# STM32L4A6 register map
File version: 1.0
CPU: CM4 r0p1, little endian, MPU, FPU, 4 interrupt priority bits
Registers are 32-bit, read-write, reset 0x0 unless marked. A register's access mark holds for its fields unless they carry their own. Offsets are from the block's base; [hi:lo] are bit positions; 'fields as' and 'values as' point back to an identical list.

## OTG_FS_PWRCLK — USB on the go full speed
Base 0x50000E00
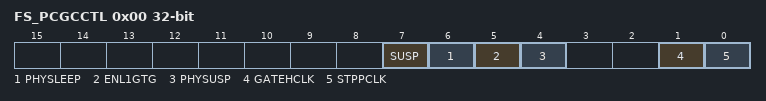
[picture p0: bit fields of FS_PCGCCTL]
0x00 FS_PCGCCTL — OTG_FS power and clock gating control register (OTG_FS_PCGCCTL)
  [7] SUSP — Deep Sleepp
  [6] PHYSLEEP — PHY in Sleep
  [5] ENL1GTG — Enable sleep clock gating
  [4] PHYSUSP — PHY Suspended
  [1] GATEHCLK
  [0] STPPCLK — Stop PHY clock

## SWPMI1 — Single Wire Protocol Master Interface
Base 0x40008800
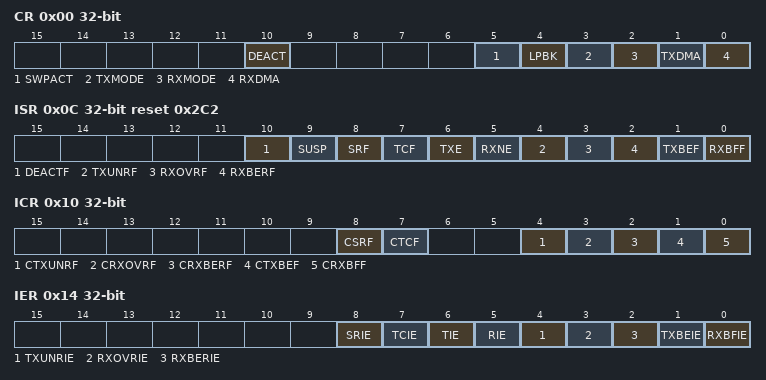
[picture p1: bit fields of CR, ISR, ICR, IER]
0x00 CR — SWPMI Configuration/Control register
  [10] DEACT — Single wire protocol master interface deactivate
  [5] SWPACT — Single wire protocol master interface activate
  [4] LPBK — Loopback mode enable
  [3] TXMODE — Transmission buffering mode
  [2] RXMODE — Reception buffering mode
  [1] TXDMA — Transmission DMA enable
  [0] RXDMA — Reception DMA enable
0x04 BRR reset 0x1 — SWPMI Bitrate register
  [5:0] BR — Bitrate prescaler
0x0C ISR ro reset 0x2C2 — SWPMI Interrupt and Status register
  [10] DEACTF — DEACTIVATED flag
  [9] SUSP — SUSPEND flag
  [8] SRF — Slave resume flag
  [7] TCF — Transfer complete flag
  [6] TXE — Transmit data register empty
  [5] RXNE — Receive data register not empty
  [4] TXUNRF — Transmit underrun error flag
  [3] RXOVRF — Receive overrun error flag
  [2] RXBERF — Receive CRC error flag
  [1] TXBEF — Transmit buffer empty flag
  [0] RXBFF — Receive buffer full flag
0x10 ICR wo — SWPMI Interrupt Flag Clear register
  [8] CSRF — Clear slave resume flag
  [7] CTCF — Clear transfer complete flag
  [4] CTXUNRF — Clear transmit underrun error flag
  [3] CRXOVRF — Clear receive overrun error flag
  [2] CRXBERF — Clear receive CRC error flag
  [1] CTXBEF — Clear transmit buffer empty flag
  [0] CRXBFF — Clear receive buffer full flag
0x14 IER — SWPMI Interrupt Enable register
  [8] SRIE — Slave resume interrupt enable
  [7] TCIE — Transmit complete interrupt enable
  [6] TIE — Transmit interrupt enable
  [5] RIE — Receive interrupt enable
  [4] TXUNRIE — Transmit underrun error interrupt enable
  [3] RXOVRIE — Receive overrun error interrupt enable
  [2] RXBERIE — Receive CRC error interrupt enable
  [1] TXBEIE — Transmit buffer empty interrupt enable
  [0] RXBFIE — Receive buffer full interrupt enable
0x18 RFL ro — SWPMI Receive Frame Length register
  [4:0] RFL — Receive frame length
0x1C TDR wo — SWPMI Transmit data register
  [31:0] TD — Transmit data
0x20 RDR ro — SWPMI Receive data register
  [31:0] RD — received data
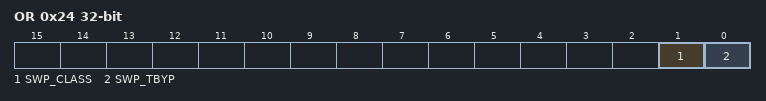
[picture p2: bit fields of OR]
0x24 OR — SWPMI Option register
  [1] SWP_CLASS — SWP class selection
  [0] SWP_TBYP — SWP transceiver bypass

## OPAMP — Operational amplifiers
Base 0x40007800
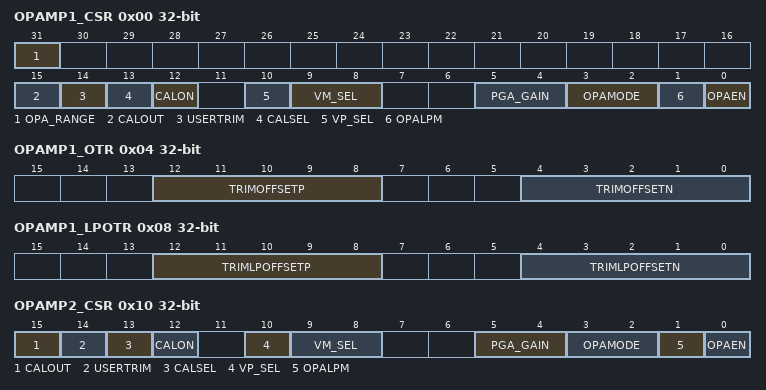
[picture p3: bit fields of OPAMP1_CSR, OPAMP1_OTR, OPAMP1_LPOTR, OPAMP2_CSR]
0x00 OPAMP1_CSR — OPAMP1 control/status register
  [31] OPA_RANGE — Operational amplifier power supply range for stability
  [15] CALOUT — Operational amplifier calibration output
  [14] USERTRIM — allows to switch from AOP offset trimmed values to AOP offset
  [13] CALSEL — Calibration selection
  [12] CALON — Calibration mode enabled
  [10] VP_SEL — Non inverted input selection
  [9:8] VM_SEL — Inverting input selection
  [5:4] PGA_GAIN — Operational amplifier Programmable amplifier gain value
  [3:2] OPAMODE — Operational amplifier PGA mode
  [1] OPALPM — Operational amplifier Low Power Mode
  [0] OPAEN — Operational amplifier Enable
0x04 OPAMP1_OTR — OPAMP1 offset trimming register in normal mode
  [12:8] TRIMOFFSETP — Trim for PMOS differential pairs
  [4:0] TRIMOFFSETN — Trim for NMOS differential pairs
0x08 OPAMP1_LPOTR — OPAMP1 offset trimming register in low-power mode
  [12:8] TRIMLPOFFSETP — Trim for PMOS differential pairs
  [4:0] TRIMLPOFFSETN — Trim for NMOS differential pairs
0x10 OPAMP2_CSR — OPAMP2 control/status register
  [15] CALOUT — Operational amplifier calibration output
  [14] USERTRIM — allows to switch from AOP offset trimmed values to AOP offset
  [13] CALSEL — Calibration selection
  [12] CALON — Calibration mode enabled
  [10] VP_SEL — Non inverted input selection
  [9:8] VM_SEL — Inverting input selection
  [5:4] PGA_GAIN — Operational amplifier Programmable amplifier gain value
  [3:2] OPAMODE — Operational amplifier PGA mode
  [1] OPALPM — Operational amplifier Low Power Mode
  [0] OPAEN — Operational amplifier Enable
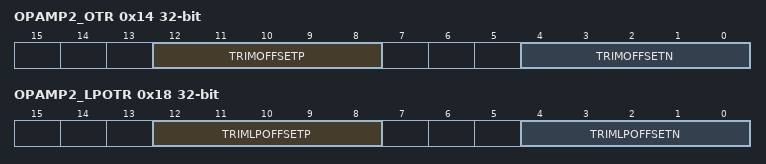
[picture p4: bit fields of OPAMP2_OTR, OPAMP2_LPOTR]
0x14 OPAMP2_OTR — OPAMP2 offset trimming register in normal mode
  fields as OPAMP1_OTR
0x18 OPAMP2_LPOTR — OPAMP2 offset trimming register in low-power mode
  fields as OPAMP1_LPOTR
